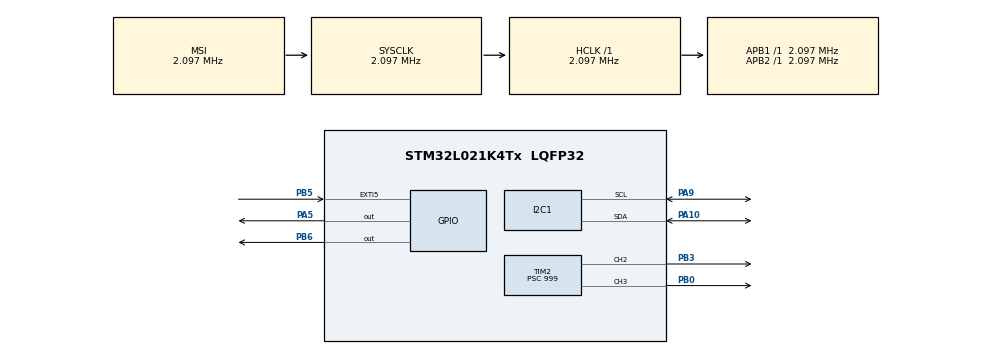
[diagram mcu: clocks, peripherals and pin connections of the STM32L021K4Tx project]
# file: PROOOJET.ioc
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Mcu.Family=STM32L0
Mcu.Name=STM32L021K4Tx
Mcu.Package=LQFP32
NVIC.I2C1_IRQn=true\:0\:0\:false\:false\:true\:true\:true
NVIC.TIM21_IRQn=true\:0\:0\:false\:false\:true\:true\:true
NVIC.TIM2_IRQn=true\:0\:0\:false\:false\:true\:true\:true
PA10.Mode=I2C
PA10.Signal=I2C1_SDA
PA13.Mode=Serial_Wire
PA13.Signal=SYS_SWDIO
PA14.Mode=Serial_Wire
PA14.Signal=SYS_SWCLK
PA5.Signal=GPIO_Output
PA9.Mode=I2C
PA9.Signal=I2C1_SCL
PB0.Signal=S_TIM2_CH3
PB3.Signal=S_TIM2_CH2
PB5.Signal=GPXTI5
PB6.Signal=GPIO_Output
ProjectManager.HeapSize=0x200
ProjectManager.StackSize=0x400
ProjectManager.TargetToolchain=STM32CubeIDE
RCC.AHBFreq_Value=2097000
RCC.APB1Freq_Value=2097000
RCC.APB1TimFreq_Value=2097000
RCC.APB2Freq_Value=2097000
RCC.APB2TimFreq_Value=2097000
RCC.HSE_VALUE=8000000
RCC.HSI16_VALUE=16000000
RCC.HSI_VALUE=16000000
RCC.LSE_VALUE=32768
RCC.MSI_VALUE=2097000
RCC.SYSCLKFreq_VALUE=2097000
RCC.VCOOutputFreq_Value=48000000
SH.S_TIM2_CH2.0=TIM2_CH2,PWM Generation2 CH2
SH.S_TIM2_CH3.0=TIM2_CH3,PWM Generation3 CH3
TIM2.Channel-PWM\ Generation2\ CH2=TIM_CHANNEL_2
TIM2.Channel-PWM\ Generation3\ CH3=TIM_CHANNEL_3
TIM2.Period=99
TIM2.Prescaler=999
TIM2.Pulse-PWM\ Generation2\ CH2=20
TIM21.Period=99
TIM21.Prescaler=9999
VP_TIM21_VS_ClockSourceINT.Mode=Internal
board=custom

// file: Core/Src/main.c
/* USER CODE BEGIN Header */
/**
  ******************************************************************************
  * @file           : main.c
  * @brief          : Main program body
  ******************************************************************************
  * @attention
  *
  * <h2><center>&copy; Copyright (c) 2022 STMicroelectronics.
  * All rights reserved.</center></h2>
  *
  * This software component is licensed by ST under BSD 3-Clause license,
  * the "License"; You may not use this file except in compliance with the
  * License. You may obtain a copy of the License at:
  *                        opensource.org/licenses/BSD-3-Clause
  *
  ******************************************************************************
  */
/* USER CODE END Header */
#include "main.h"

/* USER CODE BEGIN Includes */
#include "stdio.h"
#include "URBAN.h"

/* USER CODE END Includes */

I2C_HandleTypeDef hi2c1;

TIM_HandleTypeDef htim2;
TIM_HandleTypeDef htim21;

/* USER CODE BEGIN PV */
uint8_t INTBTN = 0;
uint8_t INTTIM12 = 1;
/* USER CODE END PV */

void SystemClock_Config(void);
static void MX_GPIO_Init(void);
static void MX_TIM2_Init(void);
static void MX_I2C1_Init(void);
static void MX_TIM21_Init(void);

int main(void)
{

  /* MCU Configuration--------------------------------------------------------*/

  /* Reset of all peripherals, Initializes the Flash interface and the Systick. */
  HAL_Init();

  /* Configure the system clock */
  SystemClock_Config();

  /* Initialize all configured peripherals */
  MX_GPIO_Init();
  MX_TIM2_Init();
  MX_I2C1_Init();
  MX_TIM21_Init();

  GPIO_PinState PinState;

  /* Infinite loop */
  /* USER CODE BEGIN WHILE */
  while (1)
  {
	 HAL_GPIO_WritePin(GPIOA, GPIO_PIN_5, 1);
	 HAL_Delay(500);
	 HAL_GPIO_WritePin(GPIOA, GPIO_PIN_5, 0);
	 HAL_Delay(200);

	 PinState=HAL_GPIO_ReadPin(GPIOB, GPIO_PIN_6);

	 if(PinState==1){
		 HAL_TIM_PWM_Start(&htim2, TIM_CHANNEL_1);
	 }

	// HAL_TIM_PWM_Stop(&htim2, TIM_CHANNEL_1);
	//HAL_TIM_PWM_Start(&htim2, TIM_CHANNEL_3);
	// URBAN();

    /* USER CODE END WHILE */

}
}

void SystemClock_Config(void)
{
  RCC_OscInitTypeDef RCC_OscInitStruct = {0};
  RCC_ClkInitTypeDef RCC_ClkInitStruct = {0};
  RCC_PeriphCLKInitTypeDef PeriphClkInit = {0};

  /** Configure the main internal regulator output voltage
  */
  __HAL_PWR_VOLTAGESCALING_CONFIG(PWR_REGULATOR_VOLTAGE_SCALE1);
  /** Initializes the RCC Oscillators according to the specified parameters
  * in the RCC_OscInitTypeDef structure.
  */
  RCC_OscInitStruct.OscillatorType = RCC_OSCILLATORTYPE_MSI;
  RCC_OscInitStruct.MSIState = RCC_MSI_ON;
  RCC_OscInitStruct.MSICalibrationValue = 0;
  RCC_OscInitStruct.MSIClockRange = RCC_MSIRANGE_5;
  RCC_OscInitStruct.PLL.PLLState = RCC_PLL_NONE;
  if (HAL_RCC_OscConfig(&RCC_OscInitStruct) != HAL_OK)
  {
    Error_Handler();
  }
  /** Initializes the CPU, AHB and APB buses clocks
  */
  RCC_ClkInitStruct.ClockType = RCC_CLOCKTYPE_HCLK|RCC_CLOCKTYPE_SYSCLK
                              |RCC_CLOCKTYPE_PCLK1|RCC_CLOCKTYPE_PCLK2;
  RCC_ClkInitStruct.SYSCLKSource = RCC_SYSCLKSOURCE_MSI;
  RCC_ClkInitStruct.AHBCLKDivider = RCC_SYSCLK_DIV1;
  RCC_ClkInitStruct.APB1CLKDivider = RCC_HCLK_DIV1;
  RCC_ClkInitStruct.APB2CLKDivider = RCC_HCLK_DIV1;

  if (HAL_RCC_ClockConfig(&RCC_ClkInitStruct, FLASH_LATENCY_0) != HAL_OK)
  {
    Error_Handler();
  }
  PeriphClkInit.PeriphClockSelection = RCC_PERIPHCLK_I2C1;
  PeriphClkInit.I2c1ClockSelection = RCC_I2C1CLKSOURCE_PCLK1;
  if (HAL_RCCEx_PeriphCLKConfig(&PeriphClkInit) != HAL_OK)
  {
    Error_Handler();
  }
}

static void MX_I2C1_Init(void)
{

  hi2c1.Instance = I2C1;
  hi2c1.Init.Timing = 0x00000708;
  hi2c1.Init.OwnAddress1 = 0;
  hi2c1.Init.AddressingMode = I2C_ADDRESSINGMODE_7BIT;
  hi2c1.Init.DualAddressMode = I2C_DUALADDRESS_DISABLE;
  hi2c1.Init.OwnAddress2 = 0;
  hi2c1.Init.OwnAddress2Masks = I2C_OA2_NOMASK;
  hi2c1.Init.GeneralCallMode = I2C_GENERALCALL_DISABLE;
  hi2c1.Init.NoStretchMode = I2C_NOSTRETCH_DISABLE;
  if (HAL_I2C_Init(&hi2c1) != HAL_OK)
  {
    Error_Handler();
  }
  /** Configure Analogue filter
  */
  if (HAL_I2CEx_ConfigAnalogFilter(&hi2c1, I2C_ANALOGFILTER_ENABLE) != HAL_OK)
  {
    Error_Handler();
  }
  /** Configure Digital filter
  */
  if (HAL_I2CEx_ConfigDigitalFilter(&hi2c1, 0) != HAL_OK)
  {
    Error_Handler();
  }

}

static void MX_TIM2_Init(void)
{

  TIM_MasterConfigTypeDef sMasterConfig = {0};
  TIM_OC_InitTypeDef sConfigOC = {0};

  htim2.Instance = TIM2;
  htim2.Init.Prescaler = 999;
  htim2.Init.CounterMode = TIM_COUNTERMODE_UP;
  htim2.Init.Period = 99;
  htim2.Init.ClockDivision = TIM_CLOCKDIVISION_DIV1;
  htim2.Init.AutoReloadPreload = TIM_AUTORELOAD_PRELOAD_DISABLE;
  if (HAL_TIM_PWM_Init(&htim2) != HAL_OK)
  {
    Error_Handler();
  }
  sMasterConfig.MasterOutputTrigger = TIM_TRGO_RESET;
  sMasterConfig.MasterSlaveMode = TIM_MASTERSLAVEMODE_DISABLE;
  if (HAL_TIMEx_MasterConfigSynchronization(&htim2, &sMasterConfig) != HAL_OK)
  {
    Error_Handler();
  }
  sConfigOC.OCMode = TIM_OCMODE_PWM1;
  sConfigOC.Pulse = 20;
  sConfigOC.OCPolarity = TIM_OCPOLARITY_HIGH;
  sConfigOC.OCFastMode = TIM_OCFAST_DISABLE;
  if (HAL_TIM_PWM_ConfigChannel(&htim2, &sConfigOC, TIM_CHANNEL_2) != HAL_OK)
  {
    Error_Handler();
  }
  sConfigOC.Pulse = 0;
  if (HAL_TIM_PWM_ConfigChannel(&htim2, &sConfigOC, TIM_CHANNEL_3) != HAL_OK)
  {
    Error_Handler();
  }
  HAL_TIM_MspPostInit(&htim2);

}

static void MX_TIM21_Init(void)
{

  TIM_ClockConfigTypeDef sClockSourceConfig = {0};
  TIM_MasterConfigTypeDef sMasterConfig = {0};

  htim21.Instance = TIM21;
  htim21.Init.Prescaler = 9999;
  htim21.Init.CounterMode = TIM_COUNTERMODE_UP;
  htim21.Init.Period = 99;
  htim21.Init.ClockDivision = TIM_CLOCKDIVISION_DIV1;
  htim21.Init.AutoReloadPreload = TIM_AUTORELOAD_PRELOAD_DISABLE;
  if (HAL_TIM_Base_Init(&htim21) != HAL_OK)
  {
    Error_Handler();
  }
  sClockSourceConfig.ClockSource = TIM_CLOCKSOURCE_INTERNAL;
  if (HAL_TIM_ConfigClockSource(&htim21, &sClockSourceConfig) != HAL_OK)
  {
    Error_Handler();
  }
  sMasterConfig.MasterOutputTrigger = TIM_TRGO_RESET;
  sMasterConfig.MasterSlaveMode = TIM_MASTERSLAVEMODE_DISABLE;
  if (HAL_TIMEx_MasterConfigSynchronization(&htim21, &sMasterConfig) != HAL_OK)
  {
    Error_Handler();
  }

}

static void MX_GPIO_Init(void)
{
  GPIO_InitTypeDef GPIO_InitStruct = {0};

  /* GPIO Ports Clock Enable */
  __HAL_RCC_GPIOA_CLK_ENABLE();
  __HAL_RCC_GPIOB_CLK_ENABLE();

  /*Configure GPIO pin Output Level */
  HAL_GPIO_WritePin(GPIOA, GPIO_PIN_5, GPIO_PIN_RESET);

  /*Configure GPIO pin Output Level */
  HAL_GPIO_WritePin(GPIOB, GPIO_PIN_6, GPIO_PIN_RESET);

  /*Configure GPIO pin : PA5 */
  GPIO_InitStruct.Pin = GPIO_PIN_5;
  GPIO_InitStruct.Mode = GPIO_MODE_OUTPUT_PP;
  GPIO_InitStruct.Pull = GPIO_NOPULL;
  GPIO_InitStruct.Speed = GPIO_SPEED_FREQ_LOW;
  HAL_GPIO_Init(GPIOA, &GPIO_InitStruct);

  /*Configure GPIO pin : PB5 */
  GPIO_InitStruct.Pin = GPIO_PIN_5;
  GPIO_InitStruct.Mode = GPIO_MODE_IT_RISING;
  GPIO_InitStruct.Pull = GPIO_NOPULL;
  HAL_GPIO_Init(GPIOB, &GPIO_InitStruct);

  /*Configure GPIO pin : PB6 */
  GPIO_InitStruct.Pin = GPIO_PIN_6;
  GPIO_InitStruct.Mode = GPIO_MODE_OUTPUT_PP;
  GPIO_InitStruct.Pull = GPIO_NOPULL;
  GPIO_InitStruct.Speed = GPIO_SPEED_FREQ_LOW;
  HAL_GPIO_Init(GPIOB, &GPIO_InitStruct);

}

void Error_Handler(void)
{
  __disable_irq();
  while (1)
  {
  }
}

/************************ (C) COPYRIGHT STMicroelectronics *****END OF FILE****/
